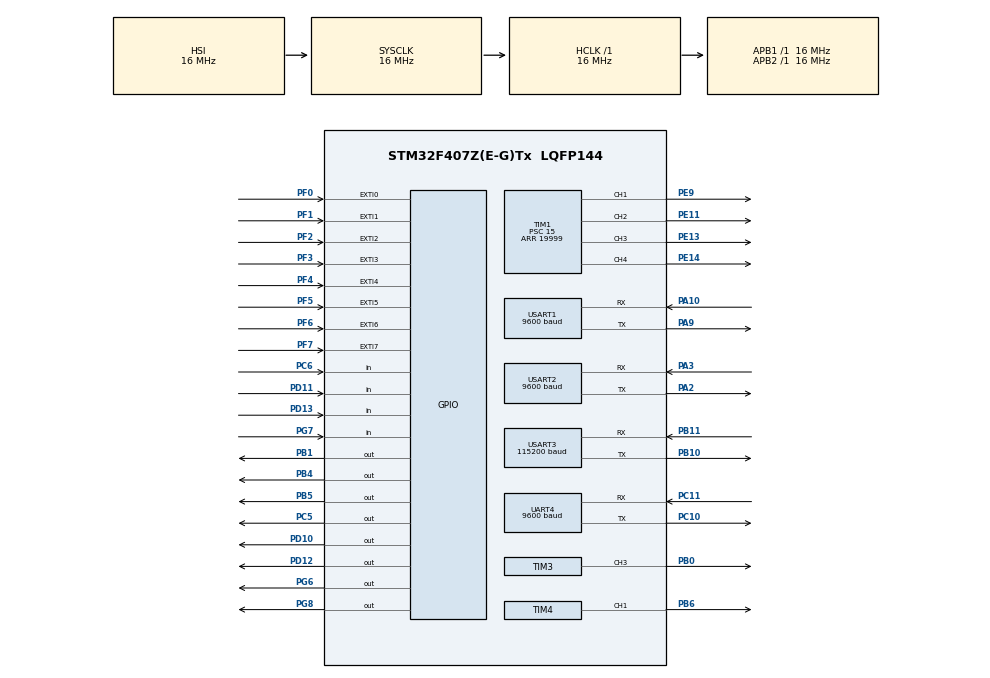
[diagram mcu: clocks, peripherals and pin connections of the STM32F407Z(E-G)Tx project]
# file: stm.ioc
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Mcu.Family=STM32F4
Mcu.Name=STM32F407Z(E-G)Tx
Mcu.Package=LQFP144
NVIC.PriorityGroup=NVIC_PRIORITYGROUP_4
NVIC.USART3_IRQn=true\:5\:0\:false\:false\:true\:true\:true\:true
PA10.Mode=Asynchronous
PA10.Signal=USART1_RX
PA2.Mode=Asynchronous
PA2.Signal=USART2_TX
PA3.Mode=Asynchronous
PA3.Signal=USART2_RX
PA9.Mode=Asynchronous
PA9.Signal=USART1_TX
PB0.Signal=S_TIM3_CH3
PB1.Signal=GPIO_Output
PB10.Mode=Asynchronous
PB10.Signal=USART3_TX
PB11.Mode=Asynchronous
PB11.Signal=USART3_RX
PB4.Signal=GPIO_Output
PB5.Signal=GPIO_Output
PB6.Signal=S_TIM4_CH1
PC10.Mode=Asynchronous
PC10.Signal=UART4_TX
PC11.Mode=Asynchronous
PC11.Signal=UART4_RX
PC5.Signal=GPIO_Output
PC6.Signal=GPIO_Input
PD10.Signal=GPIO_Output
PD11.Signal=GPIO_Input
PD12.Signal=GPIO_Output
PD13.Signal=GPIO_Input
PE11.Signal=S_TIM1_CH2
PE13.Signal=S_TIM1_CH3
PE14.Signal=S_TIM1_CH4
PE9.Signal=S_TIM1_CH1
PF0.Signal=GPXTI0
PF1.Signal=GPXTI1
PF2.Signal=GPXTI2
PF3.Signal=GPXTI3
PF4.Signal=GPXTI4
PF5.Signal=GPXTI5
PF6.Signal=GPXTI6
PF7.Signal=GPXTI7
PG6.Signal=GPIO_Output
PG7.Signal=GPIO_Input
PG8.Signal=GPIO_Output
ProjectManager.HeapSize=0x200
ProjectManager.StackSize=0x400
ProjectManager.TargetToolchain=STM32CubeIDE
RCC.AHBFreq_Value=16000000
RCC.APB1Freq_Value=16000000
RCC.APB2Freq_Value=16000000
RCC.CortexFreq_Value=16000000
RCC.HSE_VALUE=25000000
RCC.HSI_VALUE=16000000
RCC.LSE_VALUE=32768
RCC.SYSCLKFreq_VALUE=16000000
RCC.VCOOutputFreq_Value=192000000
SH.S_TIM1_CH1.0=TIM1_CH1,PWM Generation1 CH1
SH.S_TIM1_CH2.0=TIM1_CH2,PWM Generation2 CH2
SH.S_TIM1_CH3.0=TIM1_CH3,PWM Generation3 CH3
SH.S_TIM1_CH4.0=TIM1_CH4,PWM Generation4 CH4
SH.S_TIM3_CH3.0=TIM3_CH3,PWM Generation3 CH3
SH.S_TIM4_CH1.0=TIM4_CH1,PWM Generation1 CH1
TIM1.Channel-PWM\ Generation1\ CH1=TIM_CHANNEL_1
TIM1.Channel-PWM\ Generation2\ CH2=TIM_CHANNEL_2
TIM1.Channel-PWM\ Generation3\ CH3=TIM_CHANNEL_3
TIM1.Channel-PWM\ Generation4\ CH4=TIM_CHANNEL_4
TIM1.Period=19999
TIM1.Prescaler=15
TIM1.Pulse-PWM\ Generation1\ CH1=1500
TIM1.Pulse-PWM\ Generation2\ CH2=1500
TIM1.Pulse-PWM\ Generation3\ CH3=1500
TIM1.Pulse-PWM\ Generation4\ CH4=1500
TIM3.AutoReloadPreload=TIM_AUTORELOAD_PRELOAD_ENABLE
TIM3.Channel-PWM\ Generation3\ CH3=TIM_CHANNEL_3
TIM3.Period=799
TIM4.AutoReloadPreload=TIM_AUTORELOAD_PRELOAD_ENABLE
TIM4.Channel-PWM\ Generation1\ CH1=TIM_CHANNEL_1
TIM4.Period=799
UART4.BaudRate=9600
UART4.VirtualMode=Asynchronous
USART1.BaudRate=9600
USART1.VirtualMode=VM_ASYNC
USART2.BaudRate=9600
USART2.VirtualMode=VM_ASYNC
USART3.BaudRate=115200
USART3.VirtualMode=VM_ASYNC
VP_TIM1_VS_ClockSourceINT.Mode=Internal
VP_TIM3_VS_ClockSourceINT.Mode=Internal
VP_TIM4_VS_ClockSourceINT.Mode=Internal
board=custom

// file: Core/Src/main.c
/* USER CODE BEGIN Header */
/**
  ******************************************************************************
  * @file           : main.c
  * @brief          : Main program body
  ******************************************************************************
  */
/* USER CODE END Header */
#include "main.h"

/* USER CODE BEGIN Includes */
#include "app.h"
#include "car_config.h"
/* USER CODE END Includes */

TIM_HandleTypeDef htim1;
TIM_HandleTypeDef htim3;
TIM_HandleTypeDef htim4;

UART_HandleTypeDef huart4;
UART_HandleTypeDef huart1;
UART_HandleTypeDef huart2;
UART_HandleTypeDef huart3;

void SystemClock_Config(void);
static void MX_GPIO_Init(void);
static void MX_USART2_UART_Init(void);
static void MX_USART3_UART_Init(void);
static void MX_TIM1_Init(void);
static void MX_UART4_Init(void);
static void MX_USART1_UART_Init(void);
static void MX_TIM3_Init(void);
static void MX_TIM4_Init(void);

int main(void)
{

  /* MCU Configuration--------------------------------------------------------*/

  /* Reset of all peripherals, Initializes the Flash interface and the Systick. */
	HAL_Init();

  /* Configure the system clock */
  SystemClock_Config();

  /* Initialize all configured peripherals */
  MX_GPIO_Init();
  MX_USART2_UART_Init();
  MX_USART3_UART_Init();
  MX_TIM1_Init();
  MX_UART4_Init();
  MX_USART1_UART_Init();
  MX_TIM3_Init();
  MX_TIM4_Init();
  /* USER CODE BEGIN 2 */
  App_Init();
  /* USER CODE END 2 */

  /* Infinite loop */
  /* USER CODE BEGIN WHILE */
  while (1)
  {
    App_Update();
    /* USER CODE END WHILE */

  }
}

void SystemClock_Config(void)
{
  RCC_OscInitTypeDef RCC_OscInitStruct = {0};
  RCC_ClkInitTypeDef RCC_ClkInitStruct = {0};

  /** Configure the main internal regulator output voltage
  */
  __HAL_RCC_PWR_CLK_ENABLE();
  __HAL_PWR_VOLTAGESCALING_CONFIG(PWR_REGULATOR_VOLTAGE_SCALE1);

  /** Initializes the RCC Oscillators according to the specified parameters
  * in the RCC_OscInitTypeDef structure.
  */
  RCC_OscInitStruct.OscillatorType = RCC_OSCILLATORTYPE_HSI;
  RCC_OscInitStruct.HSIState = RCC_HSI_ON;
  RCC_OscInitStruct.HSICalibrationValue = RCC_HSICALIBRATION_DEFAULT;
  RCC_OscInitStruct.PLL.PLLState = RCC_PLL_NONE;
  if (HAL_RCC_OscConfig(&RCC_OscInitStruct) != HAL_OK)
  {
    Error_Handler();
  }

  /** Initializes the CPU, AHB and APB buses clocks
  */
  RCC_ClkInitStruct.ClockType = RCC_CLOCKTYPE_HCLK|RCC_CLOCKTYPE_SYSCLK
                              |RCC_CLOCKTYPE_PCLK1|RCC_CLOCKTYPE_PCLK2;
  RCC_ClkInitStruct.SYSCLKSource = RCC_SYSCLKSOURCE_HSI;
  RCC_ClkInitStruct.AHBCLKDivider = RCC_SYSCLK_DIV1;
  RCC_ClkInitStruct.APB1CLKDivider = RCC_HCLK_DIV1;
  RCC_ClkInitStruct.APB2CLKDivider = RCC_HCLK_DIV1;

  if (HAL_RCC_ClockConfig(&RCC_ClkInitStruct, FLASH_LATENCY_0) != HAL_OK)
  {
    Error_Handler();
  }
}

static void MX_TIM1_Init(void)
{

  TIM_ClockConfigTypeDef sClockSourceConfig = {0};
  TIM_MasterConfigTypeDef sMasterConfig = {0};
  TIM_OC_InitTypeDef sConfigOC = {0};
  TIM_BreakDeadTimeConfigTypeDef sBreakDeadTimeConfig = {0};

  htim1.Instance = TIM1;
  htim1.Init.Prescaler = 15;
  htim1.Init.CounterMode = TIM_COUNTERMODE_UP;
  htim1.Init.Period = 19999;
  htim1.Init.ClockDivision = TIM_CLOCKDIVISION_DIV1;
  htim1.Init.RepetitionCounter = 0;
  htim1.Init.AutoReloadPreload = TIM_AUTORELOAD_PRELOAD_DISABLE;
  if (HAL_TIM_Base_Init(&htim1) != HAL_OK)
  {
    Error_Handler();
  }
  sClockSourceConfig.ClockSource = TIM_CLOCKSOURCE_INTERNAL;
  if (HAL_TIM_ConfigClockSource(&htim1, &sClockSourceConfig) != HAL_OK)
  {
    Error_Handler();
  }
  if (HAL_TIM_PWM_Init(&htim1) != HAL_OK)
  {
    Error_Handler();
  }
  sMasterConfig.MasterOutputTrigger = TIM_TRGO_RESET;
  sMasterConfig.MasterSlaveMode = TIM_MASTERSLAVEMODE_DISABLE;
  if (HAL_TIMEx_MasterConfigSynchronization(&htim1, &sMasterConfig) != HAL_OK)
  {
    Error_Handler();
  }
  sConfigOC.OCMode = TIM_OCMODE_PWM1;
  sConfigOC.Pulse = 1500;
  sConfigOC.OCPolarity = TIM_OCPOLARITY_HIGH;
  sConfigOC.OCNPolarity = TIM_OCNPOLARITY_HIGH;
  sConfigOC.OCFastMode = TIM_OCFAST_DISABLE;
  sConfigOC.OCIdleState = TIM_OCIDLESTATE_RESET;
  sConfigOC.OCNIdleState = TIM_OCNIDLESTATE_RESET;
  if (HAL_TIM_PWM_ConfigChannel(&htim1, &sConfigOC, TIM_CHANNEL_1) != HAL_OK)
  {
    Error_Handler();
  }
  if (HAL_TIM_PWM_ConfigChannel(&htim1, &sConfigOC, TIM_CHANNEL_2) != HAL_OK)
  {
    Error_Handler();
  }
  if (HAL_TIM_PWM_ConfigChannel(&htim1, &sConfigOC, TIM_CHANNEL_3) != HAL_OK)
  {
    Error_Handler();
  }
  if (HAL_TIM_PWM_ConfigChannel(&htim1, &sConfigOC, TIM_CHANNEL_4) != HAL_OK)
  {
    Error_Handler();
  }
  sBreakDeadTimeConfig.OffStateRunMode = TIM_OSSR_DISABLE;
  sBreakDeadTimeConfig.OffStateIDLEMode = TIM_OSSI_DISABLE;
  sBreakDeadTimeConfig.LockLevel = TIM_LOCKLEVEL_OFF;
  sBreakDeadTimeConfig.DeadTime = 0;
  sBreakDeadTimeConfig.BreakState = TIM_BREAK_DISABLE;
  sBreakDeadTimeConfig.BreakPolarity = TIM_BREAKPOLARITY_HIGH;
  sBreakDeadTimeConfig.AutomaticOutput = TIM_AUTOMATICOUTPUT_DISABLE;
  if (HAL_TIMEx_ConfigBreakDeadTime(&htim1, &sBreakDeadTimeConfig) != HAL_OK)
  {
    Error_Handler();
  }
  HAL_TIM_MspPostInit(&htim1);

}

static void MX_TIM3_Init(void)
{

  TIM_ClockConfigTypeDef sClockSourceConfig = {0};
  TIM_MasterConfigTypeDef sMasterConfig = {0};
  TIM_OC_InitTypeDef sConfigOC = {0};

  htim3.Instance = TIM3;
  htim3.Init.Prescaler = 0;
  htim3.Init.CounterMode = TIM_COUNTERMODE_UP;
  htim3.Init.Period = 799;
  htim3.Init.ClockDivision = TIM_CLOCKDIVISION_DIV1;
  htim3.Init.AutoReloadPreload = TIM_AUTORELOAD_PRELOAD_ENABLE;
  if (HAL_TIM_Base_Init(&htim3) != HAL_OK)
  {
    Error_Handler();
  }
  sClockSourceConfig.ClockSource = TIM_CLOCKSOURCE_INTERNAL;
  if (HAL_TIM_ConfigClockSource(&htim3, &sClockSourceConfig) != HAL_OK)
  {
    Error_Handler();
  }
  if (HAL_TIM_PWM_Init(&htim3) != HAL_OK)
  {
    Error_Handler();
  }
  sMasterConfig.MasterOutputTrigger = TIM_TRGO_RESET;
  sMasterConfig.MasterSlaveMode = TIM_MASTERSLAVEMODE_DISABLE;
  if (HAL_TIMEx_MasterConfigSynchronization(&htim3, &sMasterConfig) != HAL_OK)
  {
    Error_Handler();
  }
  sConfigOC.OCMode = TIM_OCMODE_PWM1;
  sConfigOC.Pulse = 0;
  sConfigOC.OCPolarity = TIM_OCPOLARITY_HIGH;
  sConfigOC.OCFastMode = TIM_OCFAST_DISABLE;
  if (HAL_TIM_PWM_ConfigChannel(&htim3, &sConfigOC, TIM_CHANNEL_3) != HAL_OK)
  {
    Error_Handler();
  }
  HAL_TIM_MspPostInit(&htim3);

}

static void MX_TIM4_Init(void)
{

  TIM_ClockConfigTypeDef sClockSourceConfig = {0};
  TIM_MasterConfigTypeDef sMasterConfig = {0};
  TIM_OC_InitTypeDef sConfigOC = {0};

  htim4.Instance = TIM4;
  htim4.Init.Prescaler = 0;
  htim4.Init.CounterMode = TIM_COUNTERMODE_UP;
  htim4.Init.Period = 799;
  htim4.Init.ClockDivision = TIM_CLOCKDIVISION_DIV1;
  htim4.Init.AutoReloadPreload = TIM_AUTORELOAD_PRELOAD_ENABLE;
  if (HAL_TIM_Base_Init(&htim4) != HAL_OK)
  {
    Error_Handler();
  }
  sClockSourceConfig.ClockSource = TIM_CLOCKSOURCE_INTERNAL;
  if (HAL_TIM_ConfigClockSource(&htim4, &sClockSourceConfig) != HAL_OK)
  {
    Error_Handler();
  }
  if (HAL_TIM_PWM_Init(&htim4) != HAL_OK)
  {
    Error_Handler();
  }
  sMasterConfig.MasterOutputTrigger = TIM_TRGO_RESET;
  sMasterConfig.MasterSlaveMode = TIM_MASTERSLAVEMODE_DISABLE;
  if (HAL_TIMEx_MasterConfigSynchronization(&htim4, &sMasterConfig) != HAL_OK)
  {
    Error_Handler();
  }
  sConfigOC.OCMode = TIM_OCMODE_PWM1;
  sConfigOC.Pulse = 0;
  sConfigOC.OCPolarity = TIM_OCPOLARITY_HIGH;
  sConfigOC.OCFastMode = TIM_OCFAST_DISABLE;
  if (HAL_TIM_PWM_ConfigChannel(&htim4, &sConfigOC, TIM_CHANNEL_1) != HAL_OK)
  {
    Error_Handler();
  }
  HAL_TIM_MspPostInit(&htim4);

}

static void MX_UART4_Init(void)
{

  huart4.Instance = UART4;
  huart4.Init.BaudRate = 9600;
  huart4.Init.WordLength = UART_WORDLENGTH_8B;
  huart4.Init.StopBits = UART_STOPBITS_1;
  huart4.Init.Parity = UART_PARITY_NONE;
  huart4.Init.Mode = UART_MODE_TX_RX;
  huart4.Init.HwFlowCtl = UART_HWCONTROL_NONE;
  huart4.Init.OverSampling = UART_OVERSAMPLING_16;
  if (HAL_UART_Init(&huart4) != HAL_OK)
  {
    Error_Handler();
  }

}

static void MX_USART1_UART_Init(void)
{

  huart1.Instance = USART1;
  huart1.Init.BaudRate = 9600;
  huart1.Init.WordLength = UART_WORDLENGTH_8B;
  huart1.Init.StopBits = UART_STOPBITS_1;
  huart1.Init.Parity = UART_PARITY_NONE;
  huart1.Init.Mode = UART_MODE_TX_RX;
  huart1.Init.HwFlowCtl = UART_HWCONTROL_NONE;
  huart1.Init.OverSampling = UART_OVERSAMPLING_16;
  if (HAL_UART_Init(&huart1) != HAL_OK)
  {
    Error_Handler();
  }

}

static void MX_USART2_UART_Init(void)
{

  huart2.Instance = USART2;
  huart2.Init.BaudRate = 9600;
  huart2.Init.WordLength = UART_WORDLENGTH_8B;
  huart2.Init.StopBits = UART_STOPBITS_1;
  huart2.Init.Parity = UART_PARITY_NONE;
  huart2.Init.Mode = UART_MODE_TX_RX;
  huart2.Init.HwFlowCtl = UART_HWCONTROL_NONE;
  huart2.Init.OverSampling = UART_OVERSAMPLING_16;
  if (HAL_UART_Init(&huart2) != HAL_OK)
  {
    Error_Handler();
  }

}

static void MX_USART3_UART_Init(void)
{

  huart3.Instance = USART3;
  huart3.Init.BaudRate = 115200;
  huart3.Init.WordLength = UART_WORDLENGTH_8B;
  huart3.Init.StopBits = UART_STOPBITS_1;
  huart3.Init.Parity = UART_PARITY_NONE;
  huart3.Init.Mode = UART_MODE_TX_RX;
  huart3.Init.HwFlowCtl = UART_HWCONTROL_NONE;
  huart3.Init.OverSampling = UART_OVERSAMPLING_16;
  if (HAL_UART_Init(&huart3) != HAL_OK)
  {
    Error_Handler();
  }

}

static void MX_GPIO_Init(void)
{
  GPIO_InitTypeDef GPIO_InitStruct = {0};

  /* GPIO Ports Clock Enable */
  __HAL_RCC_GPIOF_CLK_ENABLE();
  __HAL_RCC_GPIOA_CLK_ENABLE();
  __HAL_RCC_GPIOC_CLK_ENABLE();
  __HAL_RCC_GPIOB_CLK_ENABLE();
  __HAL_RCC_GPIOE_CLK_ENABLE();
  __HAL_RCC_GPIOD_CLK_ENABLE();
  __HAL_RCC_GPIOG_CLK_ENABLE();

  /*Configure GPIO pin Output Level */
  HAL_GPIO_WritePin(GPIOC, GPIO_PIN_5, GPIO_PIN_RESET);

  /*Configure GPIO pin Output Level */
  HAL_GPIO_WritePin(GPIOB, GPIO_PIN_1|GPIO_PIN_4|GPIO_PIN_5, GPIO_PIN_RESET);

  /*Configure GPIO pin Output Level */
  HAL_GPIO_WritePin(GPIOD, GPIO_PIN_10|GPIO_PIN_12, GPIO_PIN_RESET);

  /*Configure GPIO pin Output Level */
  HAL_GPIO_WritePin(GPIOG, GPIO_PIN_6|GPIO_PIN_8, GPIO_PIN_RESET);

  /*Configure GPIO pins : PF0 PF1 PF2 PF3
                           PF4 PF5 PF6 PF7 */
  GPIO_InitStruct.Pin = GPIO_PIN_0|GPIO_PIN_1|GPIO_PIN_2|GPIO_PIN_3
                          |GPIO_PIN_4|GPIO_PIN_5|GPIO_PIN_6|GPIO_PIN_7;
  GPIO_InitStruct.Mode = GPIO_MODE_IT_RISING;
  GPIO_InitStruct.Pull = GPIO_NOPULL;
  HAL_GPIO_Init(GPIOF, &GPIO_InitStruct);

  /*Configure GPIO pin : PC5 */
  GPIO_InitStruct.Pin = GPIO_PIN_5;
  GPIO_InitStruct.Mode = GPIO_MODE_OUTPUT_PP;
  GPIO_InitStruct.Pull = GPIO_NOPULL;
  GPIO_InitStruct.Speed = GPIO_SPEED_FREQ_LOW;
  HAL_GPIO_Init(GPIOC, &GPIO_InitStruct);

  /*Configure GPIO pins : PB1 PB4 PB5 */
  GPIO_InitStruct.Pin = GPIO_PIN_1|GPIO_PIN_4|GPIO_PIN_5;
  GPIO_InitStruct.Mode = GPIO_MODE_OUTPUT_PP;
  GPIO_InitStruct.Pull = GPIO_NOPULL;
  GPIO_InitStruct.Speed = GPIO_SPEED_FREQ_LOW;
  HAL_GPIO_Init(GPIOB, &GPIO_InitStruct);

  /*Configure GPIO pins : PD10 PD12 */
  GPIO_InitStruct.Pin = GPIO_PIN_10|GPIO_PIN_12;
  GPIO_InitStruct.Mode = GPIO_MODE_OUTPUT_PP;
  GPIO_InitStruct.Pull = GPIO_NOPULL;
  GPIO_InitStruct.Speed = GPIO_SPEED_FREQ_LOW;
  HAL_GPIO_Init(GPIOD, &GPIO_InitStruct);

  /*Configure GPIO pins : PD11 PD13 */
  GPIO_InitStruct.Pin = GPIO_PIN_11|GPIO_PIN_13;
  GPIO_InitStruct.Mode = GPIO_MODE_INPUT;
  GPIO_InitStruct.Pull = GPIO_NOPULL;
  HAL_GPIO_Init(GPIOD, &GPIO_InitStruct);

  /*Configure GPIO pins : PG6 PG8 */
  GPIO_InitStruct.Pin = GPIO_PIN_6|GPIO_PIN_8;
  GPIO_InitStruct.Mode = GPIO_MODE_OUTPUT_PP;
  GPIO_InitStruct.Pull = GPIO_NOPULL;
  GPIO_InitStruct.Speed = GPIO_SPEED_FREQ_LOW;
  HAL_GPIO_Init(GPIOG, &GPIO_InitStruct);

  /*Configure GPIO pin : PG7 */
  GPIO_InitStruct.Pin = GPIO_PIN_7;
  GPIO_InitStruct.Mode = GPIO_MODE_INPUT;
  GPIO_InitStruct.Pull = GPIO_NOPULL;
  HAL_GPIO_Init(GPIOG, &GPIO_InitStruct);

  /*Configure GPIO pin : PC6 */
  GPIO_InitStruct.Pin = GPIO_PIN_6;
  GPIO_InitStruct.Mode = GPIO_MODE_INPUT;
  GPIO_InitStruct.Pull = GPIO_NOPULL;
  HAL_GPIO_Init(GPIOC, &GPIO_InitStruct);

}

void Error_Handler(void)
{
  __disable_irq();
  while (1)
  {
  }
}
